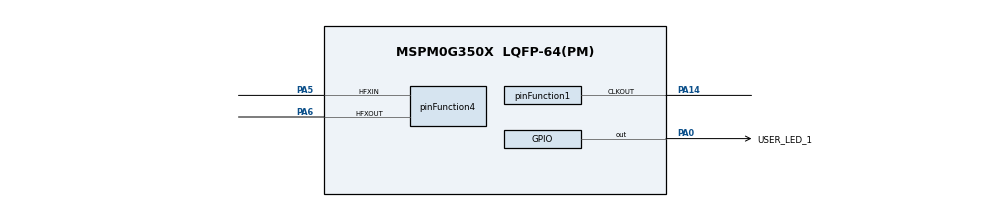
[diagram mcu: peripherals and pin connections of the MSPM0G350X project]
// @cliArgs --device "MSPM0G350X" --package "LQFP-64(PM)" --part "Default"
// @cliArgs --board /ti/boards/LP_MSPM0G3507 --rtos nortos

/**
 * Import the modules used in this configuration.
 */
const GPIO   = scripting.addModule("/ti/driverlib/GPIO", {}, false);
const GPIO1  = GPIO.addInstance();
const SYSCTL = scripting.addModule("/ti/driverlib/SYSCTL");
const TIMER  = scripting.addModule("/ti/driverlib/TIMER", {}, false);
const TIMER1 = TIMER.addInstance();

/**
 * Write custom configuration values to the imported modules.
 */
const divider1       = system.clockTree["EXCLKDIV"];
divider1.divideValue = 4;

const divider9       = system.clockTree["UDIV"];
divider9.divideValue = 2;

const gate4  = system.clockTree["EXCLKGATE"];
gate4.enable = true;

const mux3       = system.clockTree["EXCLKMUX"];
mux3.inputSelect = "EXCLKMUX_HFCLK";

const mux4       = system.clockTree["EXHFMUX"];
mux4.inputSelect = "EXHFMUX_XTAL";

const mux8       = system.clockTree["HSCLKMUX"];
mux8.inputSelect = "HSCLKMUX_HFCLK";

const pinFunction1                        = system.clockTree["CLKOUT"];
pinFunction1.enable                       = true;
pinFunction1.peripheral.clkOutPin.$assign = "PA14";

const pinFunction4                        = system.clockTree["HFXT"];
pinFunction4.enable                       = true;
pinFunction4.HFCLKMonitor                 = true;
pinFunction4.HFXTStartup                  = 10;
pinFunction4.inputFreq                    = 40;
pinFunction4.peripheral.hfxInPin.$assign  = "PA5";
pinFunction4.peripheral.hfxOutPin.$assign = "PA6";

GPIO1.port                          = "PORTA";
GPIO1.$name                         = "GPIO_LEDS";
GPIO1.associatedPins[0].$name       = "USER_LED_1";
GPIO1.associatedPins[0].assignedPin = "0";
GPIO1.associatedPins[0].pin.$assign = "PA0";

const Board = scripting.addModule("/ti/driverlib/Board", {}, false);

SYSCTL.validateClkStatus = true;
SYSCTL.forceDefaultClkConfig = true;
SYSCTL.clockTreeEn        = true;

TIMER1.$name              = "TIMER_0";
TIMER1.timerPeriod        = "500 ms";
TIMER1.interrupts         = ["ZERO"];
TIMER1.timerMode          = "PERIODIC";
TIMER1.timerClkDiv        = 4;
TIMER1.timerClkPrescale   = 129;
TIMER1.peripheral.$assign = "TIMG0";
